# platform_designer_hps_system_hps_0_hps register map
Vendor: default_vendor.com; File version: 0.0
Registers are 32-bit, read-write, reset 0x0 unless marked. A register's access mark holds for its fields unless they carry their own. Offsets are from the block's base; [hi:lo] are bit positions; {n}, {i} and the like mark numbered series.

## usb0 (part 1 of 4) — Registers in the USB OTG Controller Module. Only the Core Global, Power and Clock Gating, Data FIFO Access, and Host Port registers can be accessedin both Host and Device modes. When the USB OTG Controller is operating in one mode, either Device or Host, the application must not access registers from the other mode. If an illegal access occurs, a Mode Mismatch interrupt is generated and reflected in the Core Interrupt register (GINTSTS.ModeMis). When the core switches from one mode to another, the registers in the new mode must be reprogrammed as they would be after a power-on reset. The register address map is fixed and does not depend on the module configuration (for example, how many endpoints are implemented). Host and Device mode registers occupy different addresses.
Base 0xFFB00000
Same registers: usb1 0xFFB40000
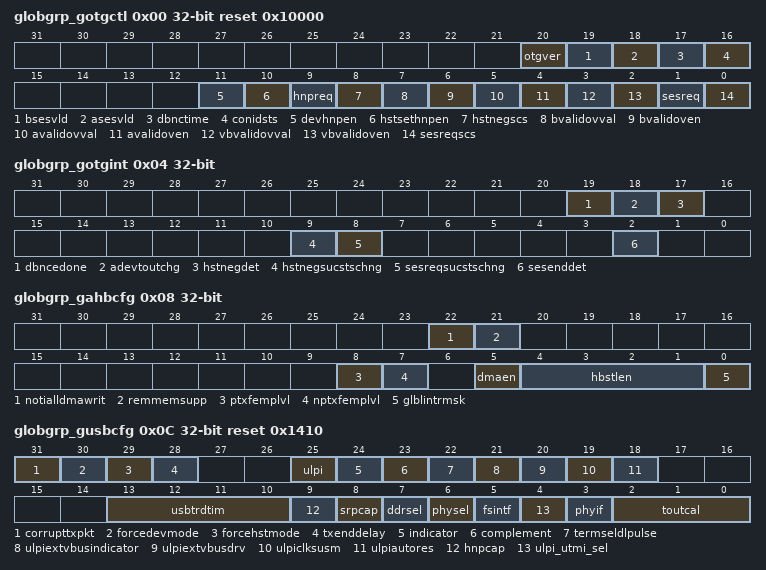
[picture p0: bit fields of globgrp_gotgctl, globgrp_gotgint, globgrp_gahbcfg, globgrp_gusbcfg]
0x00 globgrp_gotgctl reset 0x10000 — The OTG Control and Status register controls the behavior and reflects the status of the OTG function.
  [20] otgver — Indicates the OTG revision. In OTG Version 1.3. the core supports Data line pulsing and VBus pulsing for SRP. In OTG Version 2.0 the core supports only Data line pulsing for SRP.
    0=ver13; 1=ver20
  [19] bsesvld ro — Mode: Device only. Indicates the Device mode transceiver status. In OTG mode, you can use this bit to determine IF the device is connected or disconnected. If you do not enable OTG features (such as SRP and HNP), the read reset value will be 1. The vbus assigns the values internally for non-SRP or non-HNP configurations.
    0=notvalid; 1=valid
  [18] asesvld ro — Mode: Host only. Indicates the Host mode transceiver status. If you do not enabled OTG features (such as SRP and HNP), the read reset value will be 1.The vbus assigns the values internally for non-SRP or non-HNP configurations.
    0=valid; 1=notvalid
  [17] dbnctime ro — Mode: Host only. Indicates the debounce time of a detected connection.
    0=long; 1=short
  [16] conidsts ro — Mode: Host and Device. Indicates the connector ID status on a connect event.This bit is valid only for Host and Device mode.
    0=modea; 1=modeb
  [11] devhnpen — Mode: Device only. The application sets this bit when it successfully receives a SetFeature.SetHNPEnable command from the connected USB host.
    0=disabled; 1=enabled
  [10] hstsethnpen — Mode: Host only. The application sets this bit when it has successfully enabled HNP (using the SetFeature.SetHNPEnable command) on the connected device.
    0=disabled; 1=enabled
  [9] hnpreq — Mode: Device only. The application sets this bit to initiate an HNP request to the connected USB host. The application can clear this bit by writing a 0 when the Host Negotiation Success Status Change bit in the OTG Interrupt register (GOTGINT.HstNegSucStsChng) is SET.The core clears this bit when the HstNegSucStsChng bit iscleared.
    0=disabled; 1=enabled
  [8] hstnegscs ro — Mode: Device only. Host Negotiation Success (HstNegScs) The core sets this bit when host negotiation is successful. The core clears this bit when the HNP Request (HNPReq) bit in this register is SET.
    0=fail; 1=success
  [7] bvalidovval — This bit is used to set Override value for Bvalid signalwhen GOTGCTL.BvalidOvEn is set.
  [6] bvalidoven — This bit is used to enable/disable the software to override the Bvalid signal using the GOTGCTL.BvalidOvVal.
    0=disabled; 1=enabled
  [5] avalidovval — This bit is used to set Override value for Avalid signal when GOTGCTL.BvalidOvEn is set.
  [4] avalidoven — This bit is used to enable/disable the software to override the Avalid signal using the GOTGCTL.AvalidOvVal.
    0=disabled; 1=enabled
  [3] vbvalidovval — This bit is used to set Override value for vbus valid signal when GOTGCTL.VbvalidOvEn is set.
    0=set0; 1=set1
  [2] vbvalidoven — This bit is used to enable/disable the software to override the vbus-valid signal using the GOTGCTL.vbvalidOvVal..
    0=disabled; 1=enabled
  [1] sesreq — The application sets this bit to initiate a session request on the USB. The application can clear this bit by writing a 0 when the Host Negotiation Success Status Change bit in the OTG Interrupt register (GOTGINT.HstNegSucStsChng) is SET. The core clears this bit when the HstNegSucStsChng bit is cleared. If you use the USB 1.1 Full-Speed Serial Transceiver interface to initiate the session request, the application must wait until the VBUS discharges to 0.2 V, after the B-Session Valid bit in this register (GOTGCTL.BSesVld) is cleared. This discharge time varies between different PHYs and can be obtained from the PHY vendor.
    0=norequest; 1=request
  [0] sesreqscs ro — This bit is set when a session request initiation is successful. This bit is valid only For Device Only configuration when OTG_MODE == 3 or OTG_MODE == 4. Applies for device only.
    0=fail; 1=success
0x04 globgrp_gotgint ro — The application reads this register whenever there is an OTG interrupt and clears the bits in this register to clear the OTG interrupt.
  [all] fields
    0=inactive; 1=active
  [19] dbncedone — Mode: Host only. The core sets this bit when the debounce is completed after the device connect. The application can start driving USB reset after seeing this interrupt. This bit is only valid when the HNP Capable or SRP Capable bit is SET in the Core USB Configuration register (GUSBCFG.HNPCap or GUSBCFG.SRPCap, respectively). This bit can be set only by the core and the application should write 1 to clear it.
  [18] adevtoutchg — Mode:Host and Device. The core sets this bit to indicate that the A-device has timed out WHILE waiting FOR the B-device to connect. This bit can be set only by the core and the application should write 1 to clear it.
  [17] hstnegdet — Mode:Host and Device. The core sets this bit when it detects a host negotiation request on the USB. This bit can be set only by the core and the application should write 1 to clear it.
  [9] hstnegsucstschng — Mode: Host and Device. The core sets this bit on the success or failure of a USB host negotiation request. The application must read the Host Negotiation Success bit of the OTG Control and Status register (GOTGCTL.HstNegScs) to check for success or failure. This bit can be set only by the core and the application should write 1 to clear it.
  [8] sesreqsucstschng — Mode: Host and Device. The core sets this bit on the success or failure of a session request. The application must read the Session Request Success bit in the OTG Control and Status register (GOTGCTL.SesReqScs) to check for success or failure. This bit can be set only by the core and the application should write 1 to clear it.
  [2] sesenddet — Mode:Host and Device.This bit can be set only by the core and the application should write 1 to clear it.
0x08 globgrp_gahbcfg — This register can be used to configure the core after power-on or a change in mode. This register mainly contains AHB system-related configuration parameters. Do not change this register after the initial programming. The application must program this register before starting any transactions on either the AHB or the USB.
  [22] notialldmawrit — This bit is programmed to enable the System DMA Done functionality for all the DMA write Transactions corresponding to the Channel/Endpoint. This bit is valid only when GAHBCFG.RemMemSupp is set to 1.
    1=alltrans; 0=lasttrans
  [21] remmemsupp — This bit is programmed to enable/disable the functionality to wait for the system DMA Done Signal for the DMA Write Transfers. -The int_dma_req output signal is asserted when HSOTG DMA starts write transfer to the external memory. When the core is done with the Transfers it asserts int_dma_done signal to flag the completion of DMA writes from HSOTG. The core then waits for sys_dma_done signal from the system to proceed further and complete the Data Transfer corresponding to a particular Channel/Endpoint. -The int_dma_req and int_dma_done signals are not asserted and the core proceeds with the assertion of the XferComp interrupt as soon as wait for the system DMA Done Signal for the DMA Write Transfers the DMA write transfer is done at the HSOTG Core Boundary and it doesn't wait for the sys_dma_done signal to complete the DATA
    0=disabled; 1=enabled
  [8] ptxfemplvl — Mode:Host only. Indicates when the Periodic TxFIFO Empty Interrupt bit in the Core Interrupt register (GINTSTS.PTxFEmp) is triggered. This bit is used only in Slave mode.
    0=halfempty; 1=empty
  [7] nptxfemplvl — Mode:Host and device. This bit is used only in Slave mode. In host mode and with Shared FIFO with device mode, this bit indicates when the Non-Periodic TxFIFO Empty Interrupt bit in the Core Interrupt register (GINTSTS.NPTxFEmp) is triggered. With dedicated FIFO in device mode, this bit indicates when IN endpoint Transmit FIFO empty interrupt (DIEPINTn.TxFEmp) is triggered. Host mode and with Shared FIFO with device mode:
    0=halfempty; 1=empty
  [5] dmaen — Mode:Host and device. Enables switching from DMA mode to slave mode.
    0=slavemode; 1=dmamode
  [4:1] hbstlen — Mode:Host and device. This field is used in Internal DMA modes.
    0=word1orsingle; 1=word4orincr; 2=word8; 3=word16orincr4; 4=word32; 5=word64orincr8; 6=word128; 7=word256orincr16; 8=wordx
  [0] glblintrmsk — Mode: Host and device. The application uses this bit to mask or unmask the interrupt line assertion to itself. Irrespective of this bits setting, the interrupt status registers are updated by the core.
    0=mask; 1=nomask
0x0C globgrp_gusbcfg reset 0x1410 — This register can be used to configure the core after power-on or a changing to Host mode or Device mode. It contains USB and USB-PHY related configuration parameters. The application must program this register before starting any transactions on either the AHB or the USB. Do not make changes to this register after the initial programming.
  [31] corrupttxpkt wo — Mode: Host and device. This bit is for debug purposes only. Never Set this bit to 1. The application should always write 0 to this bit.
    0=nodebug; 1=debug
  [30] forcedevmode — Mode:Host and device. Writing a 1 to this bit forces the core to device mode. After setting the force bit, the application must wait at least 25 ms before the change to take effect. When the simulation is in scale down mode, waiting for 500 micro-sec is sufficient.
    0=disabled; 1=enabled
  [29] forcehstmode — Mode:Host and device. Writing a 1 to this bit forces the core to host mode After setting the force bit, the application must wait at least 25 ms before the change to take effect. When the simulation is in scale down mode, waiting for 500 micro-sec is sufficient.
    0=disabled; 1=enabled
  [28] txenddelay — Mode: Device only. Set to non UTMI+.
    0=disabled
  [25] ulpi — Mode:Host only. Controls circuitry built into the PHY for protecting the ULPI interface when the link tri-states STP and data. Any pull-ups or pull-downs employed by this feature can be disabled.
    0=enabled; 1=disabled
  [24] indicator — Mode:Host only. Controls wether the Complement Output is qualified with the Internal Vbus Valid comparator before being used in the Vbus State in the RX CMD.
    0=qualified; 1=nonqualified
  [23] complement — Mode:Host only. Controls the PHY to invert the ExternalVbusIndicator inputsignal, generating the ComplementOutput. Please refer to the ULPI Spec for more detail.
    0=noninvert; 1=invert
  [22] termseldlpulse — Mode:Device only. This bit selects utmi_termselect to drive data line pulse during SRP.
    0=txvalid; 1=termsel
  [21] ulpiextvbusindicator — Mode:Host only. This bit indicates to the ULPI PHY to use an external VBUS overcurrent indicator.
    0=intern; 1=extern
  [20] ulpiextvbusdrv — Mode:Host only. This bit selects between internal or external supply to drive 5V on VBUS, in ULPI PHY.
    0=intern; 1=extern
  [19] ulpiclksusm — Mode:Host and Device. This bit sets the ClockSuspendM bit in the Interface Control register on the ULPI PHY. This bit applies only in serial or carkit modes.
    0=pwdclk; 1=nonpwdclk
  [18] ulpiautores — Mode:Host and Device. This bit sets the AutoResume bit in the Interface Control register on the ULPI PHY.
    0=disabled; 1=enabled
  [13:10] usbtrdtim — Mode: Device only. Sets the turnaround time in PHY clocks. Specifies the response time for a MAC request to the Packet FIFO Controller (PFC) to fetch data from the DFIFO (SPRAM). The value is calculated for the minimum AHB frequency of 30 MHz. USB turnaround time is critical for certification where long cables and 5-Hubs are used, so If you need the AHB to run at less than 30 MHz, and If USB turnaround time is not critical, these bits can be programmed to a larger value.
    9=turntime
  [9] hnpcap — Mode:Host and Device. The application uses this bit to control the otg core's HNP capabilities.
    0=disabled; 1=enabled
  [8] srpcap — Mode:Host and Device. The application uses this bit to control the otg core SRP capabilities. If the core operates as a non-SRP-capable B-device, it cannot request the connected A-device (host) to activate VBUS and start a session. This bit is writable only If an SRP mode was specified for Mode of Operation in coreConsultant (parameter OTG_MODE). Otherwise, reads Return 0.
    0=disabled; 1=enabled
  [7] ddrsel — Mode:Host and Device. The application uses this bit to select a Single Data Rate (SDR) or Double Data Rate (DDR) or ULPI interface.
    0=sdr; 1=ddr
  [6] physel ro — Mode:Host and Device. The application uses USB 2.0.
    0=usb20
  [5] fsintf ro — Mode:Host and Device. The application can Set this bit to select between the 3- and 6-pin interfaces, and access is Read and Write.
    0=fs6pin; 1=fs3pin
  [4] ulpi_utmi_sel ro — Mode:Host and Device. The application uses ULPI Only in 8bit mode.
    0=ulpi
  [3] phyif ro — Mode:Host and Device. This application uses a ULPI interface only. Hence only 8-bit setting is relevant. This setting should not matter since UTMI is not enabled.
    0=bits8
  [2:0] toutcal — Mode:Host and Device. The number of PHY clocks that the application programs in this field is added to the high-speed/full-speed interpacket timeout duration in the core to account for any additional delays introduced by the PHY. This can be required, because the delay introduced by the PHY in generating the linestate condition can vary from one PHY to another. The USB standard timeout value for high-speed operation is 736 to 816 (inclusive) bit times. The USB standard timeout value for full-speed operation is 16 to 18 (inclusive) bit times. The application must program this field based on the speed of enumeration. The number of bit times added per PHY clock are: High-speed operation: -One 30-MHz PHY clock = 16 bit times -One 60-MHz PHY clock = 8 bit times Full-speed operation: -One 30-MHz PHY clock = 0.4 bit times -One 60-MHz PHY clock = 0.2 bit times -One 48-MHz PHY clock = 0.25 bit times
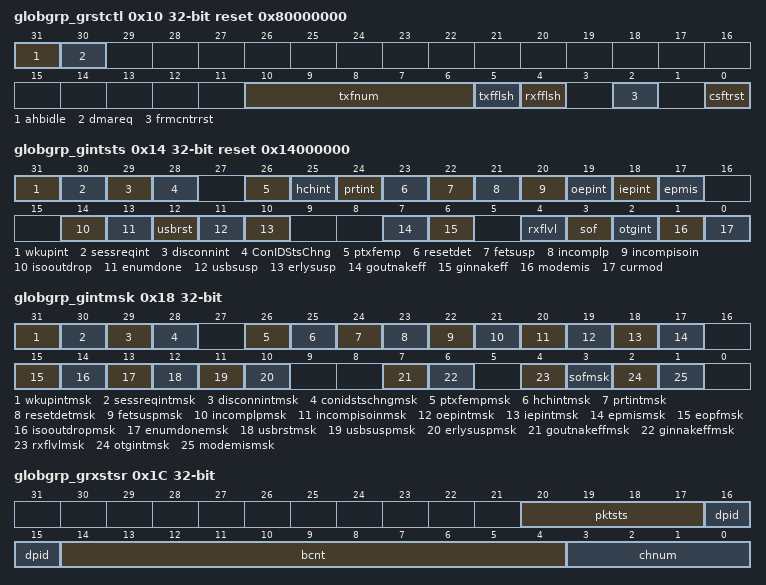
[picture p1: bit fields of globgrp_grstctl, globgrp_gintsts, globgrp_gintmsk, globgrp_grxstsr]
0x10 globgrp_grstctl reset 0x80000000 — The application uses this register to reset various hardware features inside the core
  [31] ahbidle ro — Mode:Host and Device. Indicates that the AHB Master State Machine is in the IDLE condition.
    0=inactive; 1=active
  [30] dmareq ro — Mode:Host and Device. Indicates that the DMA request is in progress. Used for debug.
    0=inactive; 1=active
  [10:6] txfnum — Mode:Host and Device. This is the FIFO number that must be flushed using the TxFIFO Flush bit. This field must not be changed until the core clears the TxFIFO Flush bit.
    0=txf0; 1=txf1; 2=txf2; 15=txf15; 16=txf16
  [5] txfflsh ro — Mode:Host and Device. This bit selectively flushes a single or all transmit FIFOs, but cannot do so If the core is in the midst of a transaction. The application must write this bit only after checking that the core is neither writing to the TxFIFO nor reading from the TxFIFO. Verify using these registers: ReadNAK Effective Interrupt ensures the core is notreading from the FIFO WriteGRSTCTL.AHBIdle ensures the core is not writinganything to the FIFO. Flushing is normally recommended when FIFOs are reconfigured or when switching between Shared FIFO and Dedicated Transmit FIFO operation. FIFO flushing is also recommended during device endpoint disable. The application must wait until the core clears this bit before performing any operations. This bit takes eight clocks to clear, using the slower clock of phy_clk or hclk.
    0=inactive; 1=active
  [4] rxfflsh ro — Mode:Host and Device. The application can flush the entire RxFIFO using this bit, but must first ensure that the core is not in the middle of a transaction. The application must only write to this bit after checking that the core is neither reading from the RxFIFO nor writing to the RxFIFO. The application must wait until the bit is cleared before performing any other operations. This bit requires 8 clocks (slowest of PHY or AHB clock) to clear.
    0=inactive; 1=active
  [2] frmcntrrst ro — Mode:Host only. The application writes this bit to reset the (micro)frame number counter inside the core. When the (micro)frame counter is reset, the subsequent SOF sent out by the core has a (micro)frame number of 0. When application writes 1 to the bit, it might not be able to read back the value as it will get cleared by the core in a few clock cycles.
    0=notactive; 1=active
  [0] csftrst ro — Mode:Host and Device. Resets the hclk and phy_clock domains as follows:Clears the interrupts and all the CSR registers except the following register bits: - PCGCCTL.RstPdwnModule - PCGCCTL.GateHclk - PCGCCTL.PwrClmp - PCGCCTL.StopPPhyLPwrClkSelclk - GUSBCFG.PhyLPwrClkSel - GUSBCFG.DDRSel - GUSBCFG.PHYSel - GUSBCFG.FSIntf - GUSBCFG.ULPI_UTMI_Sel - GUSBCFG.PHYIf - HCFG.FSLSPclkSel - DCFG.DevSpd - GGPIO - GPWRDN - GADPCTL All module state machines (except the AHB Slave Unit) are reset to the IDLE state, and all the transmit FIFOs and the receive FIFO are flushed. Any transactions on the AHB Master are terminated as soonas possible, after gracefully completing the last data phase of an AHB transfer. Any transactions on the USB are terminated immediately. When Hibernation or ADP feature is enabled, the PMU module is not reset by the Core Soft Reset.The application can write to this bit any time it wants to reset the core. This is a self-clearing bit and the core clears this bit after all the necessary logic is reset in the core, which can take several clocks, depending on the current state of the core. Once this bit is cleared software must wait at least 3 PHY clocks before doing any access to the PHY domain (synchronization delay). Software must also must check that bit 31 of this register is 1 (AHB Master is IDLE) before starting any operation.Typically software reset is used during software development and also when you dynamically change the PHY selection bits in the USB configuration registers listed above. When you change the PHY, the corresponding clock for the PHY is selected and used in the PHY domain. Once a new clock is selected, the PHY domain has to be reset for proper operation.
    0=notactive; 1=active
0x14 globgrp_gintsts ro reset 0x14000000 — This register interrupts the application for system-level events in the current mode (Device mode or Host mode). Some of the bits in this register are valid only in Host mode, while others are valid in Device mode only. This register also indicates the current mode. To clear the interrupt status bits of type R_SS_WC, the application must write 1 into the bit. The FIFO status interrupts are read only; once software reads from or writes to the FIFO while servicing these interrupts, FIFO interrupt conditions are cleared automatically. The application must clear the GINTSTS register at initialization before unmasking the interrupt bit to avoid any interrupts generated prior to initialization.
  [31] wkupint — Mode:Host and Device. Wakeup Interrupt during Suspend(L2) or LPM(L1) state. -During Suspend(L2): - Device Mode - This interrupt is asserted only when Host Initiated Resume is detected on USB. - Host Mode - This interrupt is asserted only when Device Initiated Remote Wakeup is detected on USB - During LPM(L1):- - Device Mode - This interrupt is asserted for either Host Initiated Resume or Device Initiated Remote Wakeup on USB. - Host Mode - This interrupt is asserted for either Host Initiated Resume or Device Initiated Remote Wakeup on USB.
    0=inactive; 1=active
  [30] sessreqint — Mode:Host and Device. In Host mode, this interrupt is asserted when a session request is detected from the device. In Host mode, this interrupt is asserted when a session request is detected from the device. In Device mode, this interrupt is asserted when the utmisrp_bvalid signal goes high. This bit can be set only by the core and the application should write 1 to clear.
    0=inactive; 1=active
  [29] disconnint — Mode:Host only. Asserted when a device disconnect is detected. This bit can be set only by the core and the application should write 1 to clear it.
    0=inactive; 1=active
  [28] ConIDStsChng — Mode:Host and Device. The core sets this bit when there is a change in connector ID status. This bit can be set only by the core and the application should write 1 to clear it.
    0=inactive; 1=active
  [26] ptxfemp — Mode:Host only. This interrupt is asserted when the Periodic Transmit FIFO is either half or completely empty and there is space for at least one entry to be written in the Periodic Request Queue. The half or completely empty status is determined by the Periodic TxFIFO Empty Level bit in the Core AHB Configuration register (GAHBCFG.PTxFEmpLvl).
    0=inactive; 1=active
  [25] hchint — Mode:Host only. The core sets this bit to indicate that an interrupt is pending on one of the channels of the core (in Host mode). The application must read the Host All Channels Interrupt (HAINT) register to determine the exact number of the channel on which the interrupt occurred, and Then read the corresponding Host Channel-n Interrupt (HCINTn) register to determine the exact cause of the interrupt. The application must clear the appropriate status bit in the HCINTn register to clear this bit.
    0=inactive; 1=active
  [24] prtint — Mode:Host only. The core sets this bit to indicate a change in port status of one of the otg core ports in Host mode. The application must read the Host Port Control and Status (HPRT) register to determine the exact event that caused this interrupt. The application must clear the appropriate status bit in the Host PC Control and Status register to clear this bit.
    0=inactive; 1=active
  [23] resetdet — Mode: Device only. In Device mode, this interrupt is asserted when a reset is detected on the USB in partial power-down mode when the device is in Suspend. In Host mode, this interrupt is not asserted.
    0=inactive; 1=active
  [22] fetsusp — Mode: Device only. This interrupt is valid only in DMA mode. This interrupt indicates that the core has stopped fetching data for IN endpoints due to the unavailability of TxFIFO space or Request Queue space. This interrupt is used by the application for an endpoint mismatch algorithm. for example, after detecting an endpoint mismatch, the application: - Sets a Global non-periodic IN NAK handshake - Disables In endpoints - Flushes the FIFO - Determines the token sequence from the IN Token Sequence Learning Queue - Re-enables the endpoints - Clears the Global non-periodic IN NAK handshake If the Global non-periodic IN NAK is cleared, the core has not yet fetched data for the IN endpoint, and the IN token is received: the core generates an IN token received when FIFO empty interrupt. The OTG Then sends the host a NAK response. To avoid this scenario, the application can check the GINTSTS.FetSusp interrupt, which ensures that the FIFO is full before clearing a Global NAK handshake. Alternatively, the application can mask the "IN token received when FIFO empty" interrupt when clearing a Global IN NAKhandshake.
    0=inactive; 1=active
  [21] incomplp — Mode: Device only. In Host mode, the core sets this interrupt bit when there are incomplete periodic transactions still pending which arescheduled for the current microframe. Incomplete Isochronous OUT Transfer (incompISOOUT) The Device mode, the core sets this interrupt to indicate that there is at least one isochronous OUT endpoint on which the transfer is not completed in the current microframe. This interrupt is asserted along with the End of Periodic Frame Interrupt (EOPF) bit in this register. This bit can be set only by the core and the application should write 1 to clear it
    0=inactive; 1=active
  [20] incompisoin — Mode: Device only. The core sets this interrupt to indicate that there is at least isochronous IN endpoint on which the transfer is not completed in the current microframe. This interrupt is asserted along with the End of Periodic Frame Interrupt (EOPF) bit in this register. This interrupt is not asserted in Scatter/Gather DMA mode.
    0=inactive; 1=active
  [19] oepint — Mode: Device only. The core sets this bit to indicate that an interrupt is pending on one of the OUT endpoints of the core (in Device mode). The application must read the Device All Endpoints Interrupt (DAINT) register to determine the exact number of the OUT endpoint on which the interrupt occurred, and Then read the corresponding Device OUT Endpoint-n Interrupt (DOEPINTn) register to determine the exact cause of the interrupt. The application must clear the appropriate status bit in the corresponding DOEPINTn register to clear this bit.
    0=inactive; 1=active
  [18] iepint — Mode: Device only. The core sets this bit to indicate that an interrupt is pending on one of the IN endpoints of the core (in Device mode). The application must read the Device All Endpoints Interrupt (DAINT) register to determine the exact number of the IN endpoint on Device IN Endpoint-n Interrupt (DIEPINTn) register to determine the exact cause of the interrupt. The application must clear the appropriate status bit in the corresponding DIEPINTn register to clear this bit.
    0=inactive; 1=active
  [17] epmis — Mode: Device only. This interrupt is valid only in shared FIFO operation. Indicates that an IN token has been received for a non-periodic endpoint, but the data for another endpoint is present in the top of the Non-periodic Transmit FIFO and the IN endpoint mismatch count programmed by the application has expired.
    0=inactive; 1=active
  [14] isooutdrop — Mode: Device only. The core sets this bit when it fails to write an isochronous OUT packet into the RxFIFO because the RxFIFO does not have enough space to accommodate a maximum packet size packet for the isochronous OUT endpoint.
    0=inactive; 1=active
  [13] enumdone — Mode: Device only. The core sets this bit to indicate that speed enumeration is complete. The application must read the Device Status register to obtain the enumerated speed.
    0=inactive; 1=active
  [12] usbrst — Mode: Device only. The core sets this bit to indicate that a reset is detected on the USB.
    0=inactive; 1=active
  [11] usbsusp — Mode: Device only. The core sets this bit to indicate that a suspend was detected on the USB. The core enters the Suspended state when there is no activity on the phy_line_state_i signal for an extended period of time.
    0=inactive; 1=active
  [10] erlysusp — Mode: Device only. The core sets this bit to indicate that an Idle state has been detected on the USB for 3 ms.
    0=inactive; 1=active
  [7] goutnakeff — Mode: Device only. Indicates that the Set Global OUT NAK bit in the Device Control register (DCTL.SGOUTNak), Set by the application, has taken effect in the core. This bit can be cleared by writing the Clear Global OUT NAK bit in the Device Control register (DCTL.CGOUTNak).
    0=inactive; 1=active
  [6] ginnakeff — Mode: Device only. Indicates that the Set Global Non-periodic IN NAK bit in the Device Control register (DCTL.SGNPInNak), Set by the application, has taken effect in the core. That is, the core has sampled the Global IN NAK bit Set by the application. This bit can be cleared by clearing the Clear Global Non-periodic IN NAK bit in the Device Control register (DCTL.CGNPInNak). This interrupt does not necessarily mean that a NAK handshake is sent out on the USB. The STALL bit takes precedence over the NAK bit.
    0=inactive; 1=active
  [4] rxflvl — Mode: Host and Device. Indicates that there is at least one packet pending to be read from the RxFIFO.
    0=inactive; 1=active
  [3] sof — Mode: Host and Device. In Host mode, the core sets this bit to indicate that an SOF (FS), micro-SOF (HS), or Keep-Alive (LS) is transmitted on the USB. The application must write a 1 to this bit to clear the interrupt. In Device mode, the core sets this bit to indicate that an SOF token has been received on the USB. The application can read the Device Status register to get the current (micro)Frame number. This interrupt is seen only when the core is operating at either HS or FS. This bit can be set only by the core and the application should write 1 to clear it. This register may return 1 if read immediately after power on reset. If the register bit reads 1 immediately after power on reset it does not indicate that an SOF has been sent (in case of host mode) or SOF has been received (in case of device mode). The read value of this interrupt is valid only after a valid connection between host and device is established. If the bit is set after power on reset the application can clear the bit.
    0=intactive; 1=active
  [2] otgint — Mode: Host and Device. The core sets this bit to indicate an OTG protocol event. The application must read the OTG Interrupt Status (GOTGINT) register to determine the exact event that caused this interrupt. The application must clear the appropriate status bit in the GOTGINT register to clear this bit.
    0=inactive; 1=active
  [1] modemis — Mode: Host and Device. The core sets this bit when the application is trying to access: -A Host mode register, when the core is operating in Device mode. -A Device mode register, when the core is operating in Host mode. The register access is completed on the AHB with an OKAYresponse, but is ignored by the core internally and does not affect the operation of the core. This bit can be set only by the core and the application should write 1 to clearit
    0=inactive; 1=active
  [0] curmod — Mode: Host and Device. Indicates the current mode.
    0=device; 1=host
0x18 globgrp_gintmsk — This register works with the Interrupt Register (GINTSTS) to interrupt the application. When an interrupt bit is masked, the interrupt associated with that bit is not generated. However, the GINTSTS register bit corresponding to that interrupt is still set.
  [31] wkupintmsk — Mode: Host and Device.
    0=mask; 1=nomask
  [30] sessreqintmsk — Mode: Host and Device.
    0=mask; 1=nomask
  [29] disconnintmsk — Mode: Host and Device.
    0=mask; 1=nomask
  [28] conidstschngmsk — Mode: Host and Device. This bit can be set only by the core and the application should write 1 to clear it.
    0=mask; 1=nomask
  [26] ptxfempmsk — Mode: Host only.
    0=mask; 1=nomask
  [25] hchintmsk — Mode: Host only.
    0=mask; 1=nomask
  [24] prtintmsk — Mode: Host only.
    0=mask; 1=nomask
  [23] resetdetmsk — Mode: Device only.
    0=mask; 1=nomask
  [22] fetsuspmsk — Mode: Device only.
    0=mask; 1=nomask
  [21] incomplpmsk — Mode: Host only.
    0=mask; 1=nomask
  [20] incompisoinmsk — Mode: Device only.
    0=mask; 1=nomask
  [19] oepintmsk — Mode: Device only.
    0=mask; 1=nomask
  [18] iepintmsk — Mode: Device only.
    0=mask; 1=nomaks
  [17] epmismsk — Mode: Device only.
    0=mask; 1=nomask
  [15] eopfmsk — Mode: Device only. End of Periodic Frame Interrupt Mask (EOPFMsk)
    0=mask; 1=nomask
  [14] isooutdropmsk — Mode: Device only.
    0=mask; 1=nomask
  [13] enumdonemsk — Mode: Device only.
    0=mask; 1=nomask
  [12] usbrstmsk — Mode: Device only.
    0=mask; 1=nomask
  [11] usbsuspmsk — Mode: Device only.
    0=mask; 1=nomask
  [10] erlysuspmsk — Mode: Device only.
    0=mask; 1=nomask
  [7] goutnakeffmsk — Mode: Device only.
    0=mask; 1=nomaks
  [6] ginnakeffmsk — Mode: Device only.
    0=mask; 1=nomask
  [4] rxflvlmsk — Mode: Host and Device.
    0=mask; 1=nomask
  [3] sofmsk — Mode: Host and Device.
    0=mask; 1=nomask
  [2] otgintmsk — Mode: Host and Device.
    0=mask; 1=nomask
  [1] modemismsk — Mode: Host and Device.
    0=mask; 1=nomask
0x1C globgrp_grxstsr ro — A read to the Receive Status Read and Pop register additionally pops the: top data entry out of the RxFIFO. The receive status contents must be interpreted differently in Host and Device modes. The core ignores the receive status pop/read when the receive FIFO is empty and returns a value of 0. The application must only pop the Receive Status FIFO when the Receive FIFO Non-Empty bit of the Core Interrupt register (GINTSTS.RxFLvl) is asserted. Use of these fields vary based on whether the HS OTG core is functioning as a host or a device. Do not read this register's reset value before configuring the core because the read value is "X" in the simulation.
  [20:17] pktsts — Mode: Host only. Others: Reserved. Indicates the status of the received packet
    2=indprx; 3=intrcom; 5=dttog; 7=chhalt
  [16:15] dpid — Indicates the Data PID of the received packet.
    0=data0; 2=data1; 1=data2; 3=mdata
  [14:4] bcnt — Indicates the byte count of the received data packet.
  [3:0] chnum — Indicates the endpoint number to which the current received packet belongs.
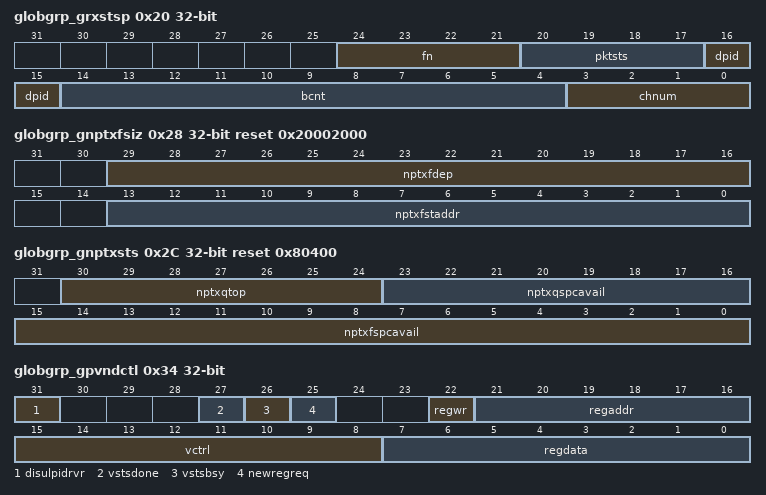
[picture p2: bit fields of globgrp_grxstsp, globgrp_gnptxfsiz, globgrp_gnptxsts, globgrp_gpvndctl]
0x20 globgrp_grxstsp ro — A read to the Receive Status Read and Pop register additionally pops the: top data entry out of the RxFIFO. The receive status contents must be interpreted differently in Host and Device modes. The core ignores the receive status pop/read when the receive FIFO is empty and returns a value of 0. The application must only pop the Receive Status FIFO when the Receive FIFO Non-Empty bit of the Core Interrupt register (GINTSTS.RxFLvl) is asserted. Use of these fields vary based on whether the HS OTG core is functioning as a host or a device. Do not read this register'ss reset value before configuring the core because the read value is "X" in the simulation.
  [24:21] fn — Mode: Device only. This is the least significant 4 bits of the (micro)Frame number in which the packet is received on the USB. This field is supported only when isochronous OUT endpoints are supported.
  [20:17] pktsts — Mode: Host only. Others: Reserved. Indicates the status of the received packet
    0=data0; 2=data1; 1=data2; 3=mdata
  [16:15] dpid — Indicates the Data PID of the received OUT data packet.
    0=data0; 2=data1; 1=data2; 3=mdata
  [14:4] bcnt — Mode: Host only. Indicates the byte count of the received IN data packet.
  [3:0] chnum — Mode: Host only. Indicates the channel number to which the current received packet belongs.
0x24 globgrp_grxfsiz reset 0x2000 — The application can program the RAM size that must be allocated to the RxFIFO.
  [13:0] rxfdep — This value is in terms of 32-bit words. Minimum value is 16 Maximum value is 32,768 The power-on reset value of this register is specified as the Largest Rx Data FIFO Dept 8192. Using the Dynamic FIFO Sizing, you can write a new value in this field. Programmed values must not exceed 8192.
0x28 globgrp_gnptxfsiz reset 0x20002000 — The application can program the RAM size and the memory start address for the Non-periodic TxFIFO. The fields of this register change, depending on host or device mode.
  [29:16] nptxfdep — Mode: Host only. for host mode, this field is always valid. The application can write a new value in this field. Programmed values must not exceed 8192
  [13:0] nptxfstaddr — Mode: Host only. for host mode, this field is always valid.This field contains the memory start address for Non-periodic Transmit FIFO RAM. This field is set from 16-8192 32 bit words. The application can write a new value in this field. Programmed values must not exceed 8192.
0x2C globgrp_gnptxsts ro reset 0x80400 — In Device mode, this register is valid only in Shared FIFO operation. It contains the free space information for the Non-periodic TxFIFO and the Nonperiodic Transmit RequestQueue
  [30:24] nptxqtop — Entry in the Non-periodic Tx Request Queue that is currently being processed by the MAC. -Bits [30:27]: Channel/endpoint number -Bits [26:25]: -Bit [24]: Terminate (last Entry for selected channel endpoint)
    0=inouttk; 1=zerotx; 2=pingcsplit; 3=chnhalt
  [23:16] nptxqspcavail — Indicates the amount of free space available in the Non-periodic Transmit Request Queue. This queue holds both IN and OUT requests in Host mode. Device mode has only IN requests. -Others: Reserved
    0=full; {v}=que{v} (v=1..8)
  [15:0] nptxfspcavail — Indicates the amount of free space available in the Non-periodic TxFIFO.Values are in terms of 32-bit words. 16h0: Non-periodic TxFIFO is full 16h1: 1 word available 16h2: 2 words available 16hn: n words available (where 0 n 32,768) 16h8000: 32,768 words available Others: Reserved
0x34 globgrp_gpvndctl — The application can use this register to access PHY registers. for a ULPI PHY, the core uses the ULPI interface for PHY register access. The application sets Vendor Control register for PHY register access and times the PHY register access. The application polls the VStatus Done bit in this register for the completion of the PHY register access
  [31] disulpidrvr ro — The application sets this bit when it has finished processing the ULPI Carkit Interrupt (GINTSTS.ULPICKINT). When Set, the otg core disables drivers for output signals and masks input signal for the ULPI interface. otg clears this bit before enabling the ULPI interface.
    0=enabled; 1=disabled
  [27] vstsdone ro — The core sets this bit when the vendor control access isdone. This bit is cleared by the core when the application sets the New Register Request bit (bit 25).
    0=inactive; 1=active
  [26] vstsbsy ro — The core sets this bit when the vendor control access is in progress and clears this bit when done.
    0=inactive; 1=active
  [25] newregreq ro — The application sets this bit for a new vendor controlaccess.
    0=inactive; 1=active
  [22] regwr — Set this bit for register writes, and clear it for register reads.
    0=read; 1=write
  [21:16] regaddr — The 6-bit PHY register address for immediate PHY Register Set access. Set to 0x2F for Extended PHY Register Set access.
  [15:8] vctrl — The 4-bit register address a vendor defined 4-bit parallel output bus. ULPI Extended Register Address and the 6-bit PHY extended register address.
  [7:0] regdata — Contains the write data for register write. Read data for register read, valid when VStatus Done is Set.
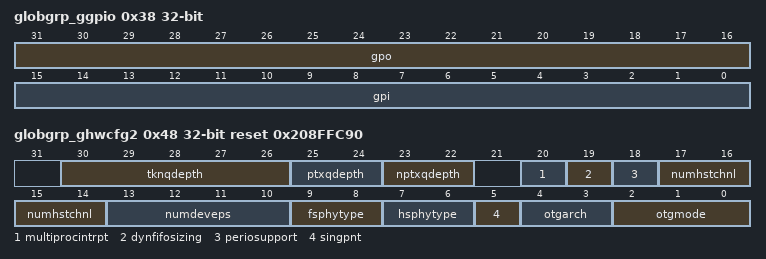
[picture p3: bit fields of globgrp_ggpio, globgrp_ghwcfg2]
0x38 globgrp_ggpio — The application can use this register for general purpose input/output ports or for debugging.
  [31:16] gpo — This field is driven as an output from the core, gp_o[15:0]. The application can program this field to determine the corresponding value on the gp_o[15:0] output.
  [15:0] gpi ro — This field's read value reflects the gp_i[15:0] core input value.
0x3C globgrp_guid reset 0x12345678 — This is a read/write register containing the User ID. This register can be used in the following ways: -To store the version or revision of your system -To store hardware configurations that are outside the otg core As a scratch register
  [31:0] guid — Application-programmable ID field.
0x40 globgrp_gsnpsid ro reset 0x4F54293A — This read-only register contains the release number of the core being used.
  [31:0] gsnpsid — Release number of the otg core being used is currently OTG 2.93a
0x44 globgrp_ghwcfg1 ro — This register contains the logical endpoint direction(s).
  [31:0] ghwcfg1 — This 32-bit field uses two bits per endpoint to determine the endpoint direction. Endpoint -Bits [31:30]: Endpoint 15 direction -Bits [29:28]: Endpoint 14 direction ... -Bits [3:2]: Endpoint 1 direction -Bits[1:0]: Endpoint 0 direction (always BIDIR)
    0=bdir; 1=inendpt; 2=outendpt
0x48 globgrp_ghwcfg2 ro reset 0x208FFC90 — This register contains configuration options.
  [30:26] tknqdepth — Range: 0 to 30.
  [25:24] ptxqdepth — Specifies the Host mode Periodic Request Queue depth.That is, the maximum number of packets that can reside in the Host Periodic TxFIFO. This queue holds one entry corresponding to each IN or OUT periodic request. This queue is 9 bits wide.
    0=que2; 1=que4; 2=que8; 3=que16
  [23:22] nptxqdepth — Specifies the Non-periodic Request Queue depth, the maximum number of packets that can reside in the Non-periodic TxFIFO. In Device mode, the queue is used only in Shared FIFO Mode (Enable Dedicated Transmit FIFO for device IN Endpoints? =No). In this mode, there is one entry in the Non-periodic Request Queue for each packet in the Non-periodic TxFIFO. In Host mode, this queue holds one entry corresponding to each IN or OUT nonperiodic request. This queue is seven bits wide.
    0=two; 1=four; 2=eight
  [20] multiprocintrpt — Not implemented.
    0=disabled
  [19] dynfifosizing — Feature supported.
    1=enabled
  [18] periosupport — Feature supported.
    1=enabled
  [17:14] numhstchnl — Indicates the number of host channels supported by the core in Host mode.
    {v}=hostch{v} (v=0..15)
  [13:10] numdeveps — The number of endpoints is 1 to 15 in Device mode in addition to control endpoint 0.
    {v}=endpt{v} (v=0..15)
  [9:8] fsphytype — Specifies the Full Speed PHY in use.
    2=fullspeed
  [7:6] hsphytype — Specifies the High Speed PHY in use.
    0=nohs; 2=ulpi
  [5] singpnt — Single Point Only.
    1=singlepoint
  [4:3] otgarch — DMA Architecture.
    2=dmamode
  [2:0] otgmode — HNP- and SRP-Capable OTG (Device and Host).
    0=hnpsrp; 1=srpotg; 2=nhnpnsrp; 3=srpcapd; 4=nonotgd; 5=srpcaph; 6=nonotgh
